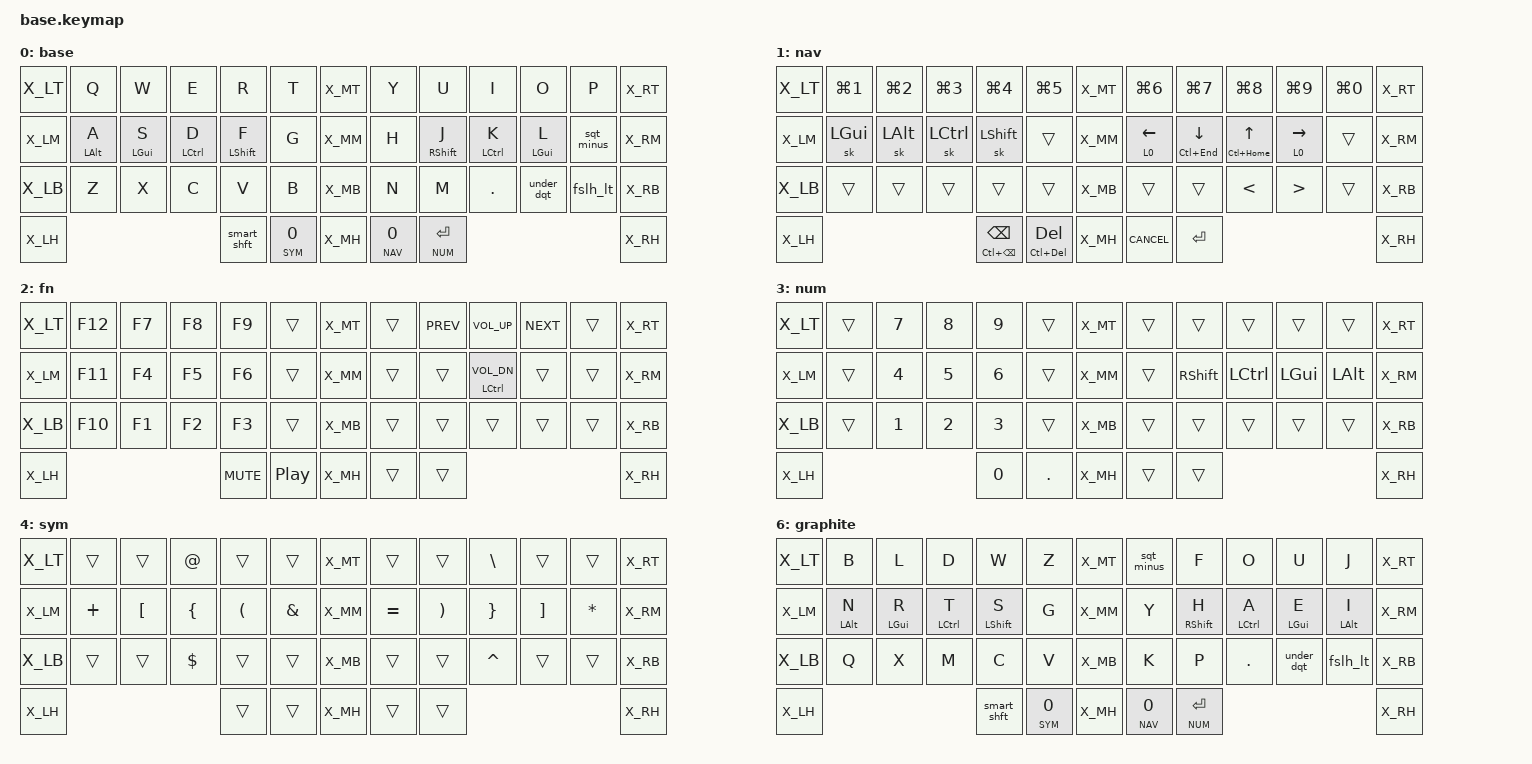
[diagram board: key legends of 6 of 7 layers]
/* Copyright (c) 2020 The ZMK Contributors
 *
 * SPDX-License-Identifier: MIT
 */

#include <behaviors.dtsi>
#include <dt-bindings/zmk/keys.h>

#include <dt-bindings/zmk/bt.h>
#define _BT_SEL_KEYS_ &bt BT_SEL 0 &bt BT_SEL 1 &bt BT_SEL 2 &bt BT_SEL 3 &bt BT_CLR

#include "../zmk-nodefree-config/helper.h"

#define DEF 0
#define NAV 1
#define FN 2
#define NUM 3
#define SYM 4
#define SYS 5
#define GRAPHITE 6

#include "combos.dtsi"
#include "extra_keys.h"

#define XXX &none
#define ___ &trans

/* Global settings */

#define QUICK_TAP_MS 175

&sk {  // sticky-key config
    release-after-ms = <900>;  // release after 0.6s
    quick-release;             // no double capitalization when rolling keys
};

&sl {  // sticky-layer config
    ignore-modifiers;          // allow chording sticky mods & layers
};

&lt {  // layer-tap config
    flavor = "balanced";
    tapping-term-ms = <200>;
    quick-tap-ms = <QUICK_TAP_MS>;
};

/* Homerow mods */

#define KEYS_L LT0 LT1 LT2 LT3 LT4 LM0 LM1 LM2 LM3 LM4 LB0 LB1 LB2 LB3 LB4  // left hand
#define KEYS_R RT0 RT1 RT2 RT3 RT4 RM0 RM1 RM2 RM3 RM4 RB0 RB1 RB2 RB3 RB4  // right hand
#define THUMBS LH2 LH1 LH0 RH0 RH1 RH2                                      // thumbs

#define MAKE_HRM(NAME, HOLD, TAP, TRIGGER_POS) \
    ZMK_BEHAVIOR(NAME, hold_tap, \
        flavor = "balanced"; \
        tapping-term-ms = <280>; \
        quick-tap-ms = <QUICK_TAP_MS>; \
        require-prior-idle-ms = <150>; \
        bindings = <HOLD>, <TAP>; \
        hold-trigger-key-positions = <TRIGGER_POS>; \
        hold-trigger-on-release; \
    )
MAKE_HRM(hml, &kp, &kp, KEYS_R THUMBS)  // left-hand HRMs
MAKE_HRM(hmr, &kp, &kp, KEYS_L THUMBS)  // right-hand HRMs


/* MAKE_HRM(hml_repeat, &kp, &key_repeat, KEYS_R THUMBS)  // used for HRM-combo */
/* MAKE_HRM(hmr_lpar, &kp, &kp, KEYS_L THUMBS)    // "    "   "   " */
/* MAKE_HRM(hmr_rpar, &kp, &kp, KEYS_R THUMBS)    // "    "   "   " */
/* Nav cluster */

// long-tap action on hold, short-tap action on all interrupts
#define MT_CORE \
    flavor = "tap-preferred"; \
    tapping-term-ms = <220>; \
    quick-tap-ms = <220>; \
    hold-trigger-key-positions = <0>;

&mt { MT_CORE };
ZMK_BEHAVIOR(mt_home, hold_tap, bindings = <&masked_home>, <&kp>; MT_CORE)
ZMK_BEHAVIOR(mt_end,  hold_tap,  bindings = <&masked_end>, <&kp>; MT_CORE)

#define NAV_LEFT  &mt_home 0   LEFT    // tap: left  | long-tap: beginning of line
#define NAV_RIGHT &mt_end 0    RIGHT   // tap: right | long-tap: end       of line
#define NAV_UP    &mt LC(HOME) UP      // tap: up    | long-tap: beginning of document
#define NAV_DOWN  &mt LC(END)  DOWN    // tap: down  | long-tap: end       of document
#define NAV_BSPC  &mt LC(BSPC) BSPC    // tap: bspc  | long-tap: delete word backward
#define NAV_DEL   &mt LC(DEL)  DEL     // tap: del   | long-tap: delete word forward

// mask CTRL when holding left/right to avoid accidental jumps to beginning/end of document
#define MASK_MODS(NAME, MODS, BINDING) \
    ZMK_BEHAVIOR(NAME, mod_morph, \
        bindings = <BINDING>, <BINDING>; \
        mods = <MODS>; \
    )
MASK_MODS(masked_home, (MOD_LCTL), &kp HOME)
MASK_MODS(masked_end,  (MOD_LCTL), &kp END)

/* Caps-word, num-word and smart-mouse */

// tap: sticky-shift | shift + tap/ double-tap: caps-word | hold: shift
ZMK_BEHAVIOR(smart_shft, mod_morph,
    bindings = <&sk LSHFT>, <&caps_word>;
    mods = <(MOD_LSFT)>;
)
&caps_word {  // mods deactivate caps-word, requires PR #1451
    /delete-property/ ignore-modifiers;
};

// tap: num-word | double-tap: sticky num-layer | hold: num-layer
#define SMART_NUM &smart_num NUM 0
ZMK_BEHAVIOR(smart_num, hold_tap,
    flavor = "balanced";
    tapping-term-ms = <200>;
    quick-tap-ms = <QUICK_TAP_MS>;
    bindings = <&mo>, <&num_dance>;
)
ZMK_BEHAVIOR(num_dance, tap_dance,
    tapping-term-ms = <200>;
    bindings = <&sl NUM>, <&num_word>;  // reverse this for sticky-num on single tap
)
&num_word {  // num-word, requires PR #1451
    layers = <NUM>;
    continue-list = <BSPC DEL DOT COMMA PLUS MINUS STAR FSLH EQUAL>;
};

// smart-mouse, requires PR #1366
/* ZMK_BEHAVIOR(smart_mouse, tri_state, */
/*     bindings = <&tog MOUSE>, <&none>, <&tog MOUSE>; */
/*     ignored-key-positions = <LT1 LT3 RT1 RT2 RT3 RM1 RM2 RM3 RH0 RH1>; */
/*     ignored-layers = <MOUSE>; */
/* ) */

/* Custom behaviors */

// Alt+Tab swapper, requires PR #1366
/* ZMK_BEHAVIOR(swapper, tri_state, */
/*     bindings = <&kt LALT>, <&kp TAB>, <&kt LALT>; */
/*     ignored-key-positions = <LT2>; */
/* ) */

// tap: space | shift + tap: dot -> space -> sticky shift | hold: activate layer
ZMK_BEHAVIOR(lt_spc, hold_tap,
    flavor = "balanced";
    tapping-term-ms = <200>;
    quick-tap-ms = <QUICK_TAP_MS>;
    bindings = <&mo>, <&spc_morph>;
)
ZMK_BEHAVIOR(spc_morph, mod_morph,
    bindings = <&kp SPACE>, <&dot_spc>;
    mods = <(MOD_LSFT|MOD_RSFT)>;
)
ZMK_BEHAVIOR(dot_spc, macro,
    wait-ms = <0>;
    tap-ms = <5>;
    bindings = <&kp DOT &kp SPACE &sk LSHFT>;
)

ZMK_BEHAVIOR(grave_pipe, mod_morph,
    bindings = <&kp GRAVE>, <&kp PIPE>;
    mods = <(MOD_LSFT|MOD_RSFT)>; 
)

ZMK_BEHAVIOR(excl_prcnt, mod_morph,
    bindings = <&kp EXCL>, <&kp PRCNT>;
    mods = <(MOD_LSFT|MOD_RSFT)>; 
)

ZMK_BEHAVIOR(tilde_hash, mod_morph,
    bindings = <&kp TILDE>, <&kp HASH>;
    mods = <(MOD_LSFT|MOD_RSFT)>; 
)

ZMK_BEHAVIOR(sqt_minus, mod_morph,
    bindings = <&kp SQT>, <&kp MINUS>;
    mods = <(MOD_LSFT|MOD_RSFT)>; 
)

ZMK_BEHAVIOR(comma_qmark, mod_morph,
    bindings = <&kp COMMA>, <&kp QMARK>;
    mods = <(MOD_LSFT|MOD_RSFT)>; 
)

ZMK_BEHAVIOR(under_dqt, mod_morph,
    bindings = <&kp UNDER>, <&kp DQT>;
    mods = <(MOD_LSFT|MOD_RSFT)>; 
)

ZMK_BEHAVIOR(fslh_lt, mod_morph,
    bindings = <&kp FSLH>, <&kp LT>;
    mods = <(MOD_LSFT|MOD_RSFT)>; 
)

// tap: backspace | lshft + tap: delete | rshft + tap: shift-delete
ZMK_BEHAVIOR(bs_del, mod_morph,
    bindings = <&kp BSPC>, <&kp DEL>;
    mods = <(MOD_LSFT|MOD_RSFT)>;
    keep-mods = <MOD_RSFT>;
)

#define SYM_DEL &lt_bs_del SYM 0
ZMK_BEHAVIOR(lt_bs_del, hold_tap,
    flavor = "balanced";
    tapping-term-ms = <200>;
    quick-tap-ms = <QUICK_TAP_MS>;
    bindings = <&mo>, <&bs_del>;
)

// misc aliases
#define CANCEL      &kp K_CANCEL             // cancel caps-word, num-word and smart-mouse
#define VOL_DOWN    &hmr LCTRL C_VOL_DN

ZMK_CONDITIONAL_LAYER(SYM NAV, SYS)  // FN + NUM --> SYS
                                     //
ZMK_LAYER(base,
//╭──────╮ ╭─────────────┬─────────────┬─────────────┬─────────────┬─────────────╮ ╭──────╮ ╭─────────────┬─────────────┬─────────────┬─────────────┬─────────────╮ ╭──────╮
    X_LT     &kp Q         &kp W         &kp E         &kp R         &kp T           X_MT     &kp Y         &kp U         &kp I         &kp O         &kp P           X_RT
//├──────┤ ├─────────────┼─────────────┼─────────────┼─────────────┼─────────────┤ ├──────┤ ├─────────────┼─────────────┼─────────────┼─────────────┼─────────────┤ ├──────┤
    X_LM     &hml LALT A   &hml LGUI S   &hml LCTRL D  &hml LSHFT F  &kp G           X_MM     &kp H         &hmr RSHFT J  &hmr LCTRL K  &hmr LGUI L   &sqt_minus      X_RM
//├──────┤ ├─────────────┼─────────────┼─────────────┼─────────────┼─────────────┤ ├──────┤ ├─────────────┼─────────────┼─────────────┼─────────────┼─────────────┤ ├──────┤
    X_LB     &kp Z         &kp X         &kp C         &kp V         &kp B           X_MB     &kp N         &kp M         &kp DOT       &under_dqt    &fslh_lt        X_RB
//├──────┤ ╰─────────────┼─────────────┴─────────────┼─────────────┼─────────────┤ ├──────┤ ├─────────────┼─────────────┼─────────────┴───────────────────────────╯ ├──────┤
    X_LH                                               &smart_shft   SYM_DEL         X_MH     &lt_spc NAV 0 &lt NUM RET                                               X_RH
//╰──────╯                                           ╰─────────────┴─────────────╯ ╰──────╯ ╰─────────────┴─────────────╯                                           ╰──────╯
)

ZMK_LAYER(nav,
//╭──────╮ ╭─────────────┬─────────────┬─────────────┬─────────────┬─────────────╮ ╭──────╮ ╭─────────────┬─────────────┬─────────────┬─────────────┬─────────────╮ ╭──────╮
    X_LT     &kp LG(N1)    &kp LG(N2)    &kp LG(N3)    &kp LG(N4)    &kp LG(N5)      X_MT     &kp LG(N6)    &kp LG(N7)    &kp LG(N8)    &kp LG(N9)    &kp LG(N0)      X_RT
//├──────┤ ├─────────────┼─────────────┼─────────────┼─────────────┼─────────────┤ ├──────┤ ├─────────────┼─────────────┼─────────────┼─────────────┼─────────────┤ ├──────┤
    X_LM     &sk LGUI      &sk LALT      &sk LCTRL     &sk LSHFT     ___             X_MM     NAV_LEFT      NAV_DOWN      NAV_UP        NAV_RIGHT     ___             X_RM
//├──────┤ ├─────────────┼─────────────┼─────────────┼─────────────┼─────────────┤ ├──────┤ ├─────────────┼─────────────┼─────────────┼─────────────┼─────────────┤ ├──────┤
    X_LB     ___           ___           ___           ___           ___             X_MB     ___           ___           &kp LT        &kp GT        ___             X_RB
//├──────┤ ╰─────────────┼─────────────┴─────────────┼─────────────┼─────────────┤ ├──────┤ ├─────────────┼─────────────┼─────────────┴─────────────┴─────────────╯ ├──────┤
    X_LH                                               NAV_BSPC      NAV_DEL         X_MH     CANCEL        &kp RET                                                   X_RH
//╰──────╯                                           ╰─────────────┴─────────────╯ ╰──────╯ ╰─────────────┴─────────────╯                                           ╰──────╯
)

ZMK_LAYER(fn,
//╭──────╮ ╭─────────────┬─────────────┬─────────────┬─────────────┬─────────────╮ ╭──────╮ ╭─────────────┬─────────────┬─────────────┬─────────────┬─────────────╮ ╭──────╮
    X_LT     &kp F12       &kp F7        &kp F8        &kp F9        ___             X_MT     ___           &kp C_PREV    &kp C_VOL_UP  &kp C_NEXT    ___             X_RT
//├──────┤ ├─────────────┼─────────────┼─────────────┼─────────────┼─────────────┤ ├──────┤ ├─────────────┼─────────────┼─────────────┼─────────────┼─────────────┤ ├──────┤
    X_LM     &kp F11       &kp F4        &kp F5        &kp F6        ___             X_MM     ___           ___           VOL_DOWN      ___           ___             X_RM
//├──────┤ ├─────────────┼─────────────┼─────────────┼─────────────┼─────────────┤ ├──────┤ ├─────────────┼─────────────┼─────────────┼─────────────┼─────────────┤ ├──────┤
    X_LB     &kp F10       &kp F1        &kp F2        &kp F3        ___             X_MB     ___           ___           ___           ___           ___             X_RB
//├──────┤ ╰─────────────┼─────────────┴─────────────┼─────────────┼─────────────┤ ├──────┤ ├─────────────┼─────────────┼─────────────┴─────────────┴─────────────╯ ├──────┤
    X_LH                                               &kp C_MUTE    &kp C_PP        X_MH     ___           ___                                                       X_RH
//╰──────╯                                           ╰─────────────┴─────────────╯ ╰──────╯ ╰─────────────┴─────────────╯                                           ╰──────╯
)

ZMK_LAYER(num,
//╭──────╮ ╭─────────────┬─────────────┬─────────────┬─────────────┬─────────────╮ ╭──────╮ ╭─────────────┬─────────────┬─────────────┬─────────────┬─────────────╮ ╭──────╮
    X_LT     ___           &kp N7        &kp N8        &kp N9        ___             X_MT     ___           ___           ___           ___           ___             X_RT
//├──────┤ ├─────────────┼─────────────┼─────────────┼─────────────┼─────────────┤ ├──────┤ ├─────────────┼─────────────┼─────────────┼─────────────┼─────────────┤ ├──────┤
    X_LM     ___           &kp N4        &kp N5        &kp N6        ___             X_MM     ___           &kp RSHFT     &kp LCTRL     &kp LGUI      &kp LALT        X_RM
//├──────┤ ├─────────────┼─────────────┼─────────────┼─────────────┼─────────────┤ ├──────┤ ├─────────────┼─────────────┼─────────────┼─────────────┼─────────────┤ ├──────┤
    X_LB     ___           &kp N1        &kp N2        &kp N3        ___             X_MB     ___           ___           ___           ___           ___             X_RB
//├──────┤ ╰─────────────┼─────────────┴─────────────┼─────────────┼─────────────┤ ├──────┤ ├─────────────┼─────────────┼─────────────┴─────────────┴─────────────╯ ├──────┤
    X_LH                                               &kp N0        &kp DOT         X_MH     ___           ___                                                       X_RH
//╰──────╯                                           ╰─────────────┴─────────────╯ ╰──────╯ ╰─────────────┴─────────────╯                                           ╰──────╯
)

//
ZMK_LAYER(sym,
//╭──────╮ ╭─────────────┬─────────────┬─────────────┬─────────────┬─────────────╮ ╭──────╮ ╭─────────────┬─────────────┬─────────────┬─────────────┬─────────────╮ ╭──────╮
    X_LT     ___           ___           &kp AT        ___           ___             X_MT     ___           ___           &kp BSLH      ___           ___             X_RT
//├──────┤ ├─────────────┼─────────────┼─────────────┼─────────────┼─────────────┤ ├──────┤ ├─────────────┼─────────────┼─────────────┼─────────────┼─────────────┤ ├──────┤
    X_LM     &kp PLUS      &kp LBKT      &kp LBRC      &kp LPAR      &kp AMPS        X_MM     &kp EQUAL     &kp RPAR      &kp RBRC      &kp RBKT      &kp STAR        X_RM
//├──────┤ ├─────────────┼─────────────┼─────────────┼─────────────┼─────────────┤ ├──────┤ ├─────────────┼─────────────┼─────────────┼─────────────┼─────────────┤ ├──────┤
    X_LB     ___           ___           &kp DLLR      ___           ___             X_MB     ___           ___           &kp CARET     ___           ___             X_RB
//├──────┤ ╰─────────────┼─────────────┴─────────────┼─────────────┼─────────────┤ ├──────┤ ├─────────────┼─────────────┼─────────────┴─────────────┴─────────────╯ ├──────┤
    X_LH                                               ___           ___             X_MH     ___           ___                                                       X_RH
//╰──────╯                                           ╰─────────────┴─────────────╯ ╰──────╯ ╰───────────────────────────╯                                           ╰──────╯
)

ZMK_LAYER(sys,
//╭──────╮ ╭─────────────┬─────────────┬─────────────┬─────────────┬─────────────╮ ╭──────╮ ╭─────────────┬─────────────┬─────────────┬─────────────┬─────────────╮ ╭──────╮
    X_LT                                _BT_SEL_KEYS_                                X_MT     ___           ___           ___           ___           ___             X_RT
//├──────┤ ├─────────────┼─────────────┼─────────────┼─────────────┼─────────────┤ ├──────┤ ├─────────────┼─────────────┼─────────────┼─────────────┼─────────────┤ ├──────┤
    X_LM     ___           ___           ___           ___           &bootloader     X_MM     &bootloader   ___           ___           ___           ___             X_RM
//├──────┤ ├─────────────┼─────────────┼─────────────┼─────────────┼─────────────┤ ├──────┤ ├─────────────┼─────────────┼─────────────┼─────────────┼─────────────┤ ├──────┤
    X_LB     ___           ___           ___           ___           &sys_reset      X_MB     &sys_reset    ___           ___           ___           ___             X_RB
//├──────┤ ╰─────────────┼─────────────┴─────────────┼─────────────┼─────────────┤ ├──────┤ ├─────────────┼─────────────┼─────────────┴─────────────┴─────────────╯ ├──────┤
    X_LH                                               ___           ___             X_MH     ___           ___                                                       X_RH
//╰──────╯                                           ╰─────────────┴─────────────╯ ╰──────╯ ╰─────────────┴─────────────╯                                           ╰──────╯
)

ZMK_LAYER(graphite,
//╭──────╮ ╭─────────────┬─────────────┬─────────────┬─────────────┬─────────────╮ ╭──────╮ ╭─────────────┬─────────────┬─────────────┬─────────────┬─────────────╮ ╭──────╮
    X_LT     &kp B         &kp L         &kp D         &kp W         &kp Z           X_MT     &sqt_minus    &kp F         &kp O         &kp U         &kp J           X_RT
//├──────┤ ├─────────────┼─────────────┼─────────────┼─────────────┼─────────────┤ ├──────┤ ├─────────────┼─────────────┼─────────────┼─────────────┼─────────────┤ ├──────┤
    X_LM     &hml LALT N   &hml LGUI R   &hml LCTRL T  &hml LSHFT S  &kp G           X_MM     &kp Y         &hmr RSHFT H  &hmr LCTRL A  &hmr LGUI E   &hmr LALT I     X_RM
//├──────┤ ├─────────────┼─────────────┼─────────────┼─────────────┼─────────────┤ ├──────┤ ├─────────────┼─────────────┼─────────────┼─────────────┼─────────────┤ ├──────┤
    X_LB     &kp Q         &kp X         &kp M         &kp C         &kp V           X_MB     &kp K         &kp P         &kp DOT       &under_dqt    &fslh_lt        X_RB
//├──────┤ ╰─────────────┼─────────────┴─────────────┼─────────────┼─────────────┤ ├──────┤ ├─────────────┼─────────────┼─────────────┴───────────────────────────╯ ├──────┤
    X_LH                                               &smart_shft   SYM_DEL         X_MH     &lt_spc NAV 0 &lt NUM RET                                               X_RH
//╰──────╯                                           ╰─────────────┴─────────────╯ ╰──────╯ ╰─────────────┴─────────────╯                                           ╰──────╯
)


// ZMK_LAYER(mouse,
//╭──────╮ ╭─────────────┬─────────────┬─────────────┬─────────────┬─────────────╮ ╭──────╮ ╭─────────────┬─────────────┬─────────────┬─────────────┬─────────────╮ ╭──────╮
//    X_LT     ___           ___           ___           ___           ___             X_MT     ___           U_WH_D        U_MS_U         U_WH_U       ___             X_RT
//├──────┤ ├─────────────┼─────────────┼─────────────┼─────────────┼─────────────┤ ├──────┤ ├─────────────┼─────────────┼─────────────┼─────────────┼─────────────┤ ├──────┤
//    X_LM     ___           ___           ___           ___           ___             X_MM     ___           U_MS_L        U_MS_D         U_MS_R       ___             X_RM
//├──────┤ ├─────────────┼─────────────┼─────────────┼─────────────┼─────────────┤ ├──────┤ ├─────────────┼─────────────┼─────────────┼─────────────┼─────────────┤ ├──────┤
//    X_LB     ___           ___           ___           ___           ___             X_MB     ___           ___           ___            ___          ___             X_RB
//├──────┤ ╰─────────────┼─────────────┴─────────────┼─────────────┼─────────────┤ ├──────┤ ├─────────────┼─────────────┼─────────────┴───────────────────────────╯ ├──────┤
//    X_LH                                               ___           ___             X_MH     U_BTN2        U_BTN1                                                    X_RH
//╰──────╯                                           ╰─────────────┴─────────────╯ ╰──────╯ ╰─────────────┴─────────────╯                                           ╰──────╯
//)

/* vim: set ft=c tw=174: */
